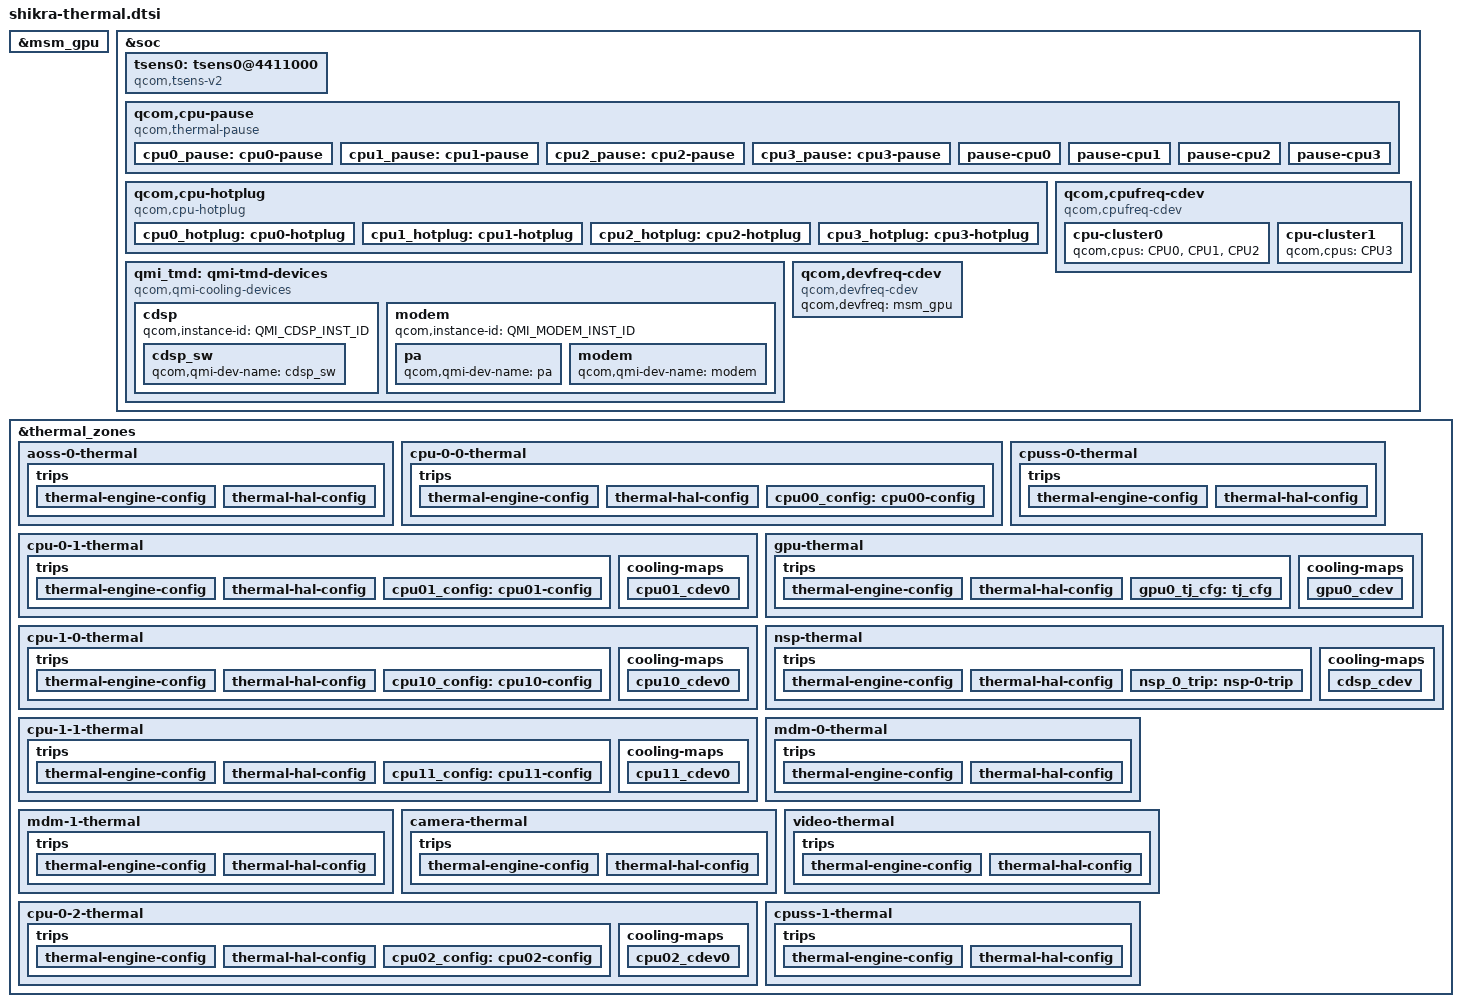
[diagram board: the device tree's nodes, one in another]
// SPDX-License-Identifier: BSD-3-Clause
/*
 * Copyright (c) Qualcomm Technologies, Inc. and/or its subsidiaries.
 */

#include <dt-bindings/thermal/thermal_qti.h>

&msm_gpu {
	#cooling-cells = <2>;
};

&soc {
	tsens0: tsens0@4411000 {
		compatible = "qcom,tsens-v2";
		reg = <0x04411000 0x1ff>, /* TM */
				<0x04410000 0x1ff>; /* SROT */
		#qcom,sensors = <14>;
		interrupts = <GIC_SPI 275 IRQ_TYPE_LEVEL_HIGH>,
				<GIC_SPI 190 IRQ_TYPE_LEVEL_HIGH>;
		interrupt-names = "uplow","critical";
		#thermal-sensor-cells = <1>;
	};

	qcom,cpu-pause {
		compatible = "qcom,thermal-pause";
		cpu0_pause: cpu0-pause {
			qcom,cpus = <&CPU0>;
			qcom,cdev-alias = "thermal-pause-1";
			#cooling-cells = <2>;
		};

		cpu1_pause: cpu1-pause {
			qcom,cpus = <&CPU1>;
			qcom,cdev-alias = "thermal-pause-2";
			#cooling-cells = <2>;
		};

		cpu2_pause: cpu2-pause {
			qcom,cpus = <&CPU2>;
			qcom,cdev-alias = "thermal-pause-4";
			#cooling-cells = <2>;
		};

		cpu3_pause: cpu3-pause {
			qcom,cpus = <&CPU3>;
			qcom,cdev-alias = "thermal-pause-8";
			#cooling-cells = <2>;
		};

		/* Thermal-engine cooling devices */
		pause-cpu0 {
			qcom,cpus = <&CPU0>;
			qcom,cdev-alias = "pause-cpu0";
		};

		pause-cpu1 {
			qcom,cpus = <&CPU1>;
			qcom,cdev-alias = "pause-cpu1";
		};

		pause-cpu2 {
			qcom,cpus = <&CPU2>;
			qcom,cdev-alias = "pause-cpu2";
		};

		pause-cpu3 {
			qcom,cpus = <&CPU3>;
			qcom,cdev-alias = "pause-cpu3";
		};
	};

	qcom,cpu-hotplug {
		compatible = "qcom,cpu-hotplug";
		cpu0_hotplug: cpu0-hotplug {
			qcom,cpu = <&CPU0>;
			qcom,cdev-alias = "cpu-hotplug0";
			#cooling-cells = <2>;
		};

		cpu1_hotplug: cpu1-hotplug {
			qcom,cpu = <&CPU1>;
			qcom,cdev-alias = "cpu-hotplug1";
			#cooling-cells = <2>;
		};

		cpu2_hotplug: cpu2-hotplug {
			qcom,cpu = <&CPU2>;
			qcom,cdev-alias = "cpu-hotplug2";
			#cooling-cells = <2>;
		};

		cpu3_hotplug: cpu3-hotplug {
			qcom,cpu = <&CPU3>;
			qcom,cdev-alias = "cpu-hotplug3";
			#cooling-cells = <2>;
		};
	};

	qcom,cpufreq-cdev {
		compatible = "qcom,cpufreq-cdev";
		cpu-cluster0 {
			qcom,cpus = <&CPU0 &CPU1 &CPU2>;
		};

		cpu-cluster1 {
			qcom,cpus = <&CPU3>;
		};
	};

	qmi_tmd: qmi-tmd-devices {
		compatible = "qcom,qmi-cooling-devices";
		cdsp {
			qcom,instance-id = <QMI_CDSP_INST_ID>;

			cdsp_sw: cdsp_sw {
				qcom,qmi-dev-name = "cdsp_sw";
				#cooling-cells = <2>;
			};
		};

		modem {
			qcom,instance-id = <QMI_MODEM_INST_ID>;

			pa: pa {
				qcom,qmi-dev-name = "pa";
				#cooling-cells = <2>;
			};

			modem: modem {
				qcom,qmi-dev-name = "modem";
				#cooling-cells = <2>;
			};
		};
	};

	qcom,devfreq-cdev {
		compatible = "qcom,devfreq-cdev";
		qcom,devfreq = <&msm_gpu>;
	};
};

&thermal_zones {
	aoss-0-thermal {
		polling-delay-passive = <0>;
		polling-delay = <0>;
		thermal-sensors = <&tsens0 0>;
		trips {
			thermal-engine-config {
				temperature = <125000>;
				hysteresis = <5000>;
				type = "passive";
			};

			thermal-hal-config {
				temperature = <115000>;
				hysteresis = <5000>;
				type = "passive";
			};
		};
	};

	cpu-0-0-thermal {
		polling-delay-passive = <0>;
		polling-delay = <0>;
		thermal-sensors = <&tsens0 1>;
		trips {
			thermal-engine-config {
				temperature = <125000>;
				hysteresis = <5000>;
				type = "passive";
			};

			thermal-hal-config {
				temperature = <115000>;
				hysteresis = <5000>;
				type = "passive";
			};

			cpu00_config: cpu00-config {
				temperature = <118000>;
				hysteresis = <10000>;
				type = "passive";
			};
		};
	};

	cpu-0-1-thermal {
		polling-delay-passive = <0>;
		polling-delay = <0>;
		thermal-sensors = <&tsens0 2>;
		trips {
			thermal-engine-config {
				temperature = <125000>;
				hysteresis = <5000>;
				type = "passive";
			};

			thermal-hal-config {
				temperature = <115000>;
				hysteresis = <5000>;
				type = "passive";
			};

			cpu01_config: cpu01-config {
				temperature = <118000>;
				hysteresis = <10000>;
				type = "passive";
			};
		};

		cooling-maps {
			cpu01_cdev0 {
				trip = <&cpu01_config>;
				cooling-device = <&cpu1_pause 0 1>;
			};
		};
	};

	cpu-1-0-thermal {
		polling-delay-passive = <0>;
		polling-delay = <0>;
		thermal-sensors = <&tsens0 3>;
		trips {
			thermal-engine-config {
				temperature = <125000>;
				hysteresis = <5000>;
				type = "passive";
			};

			thermal-hal-config {
				temperature = <115000>;
				hysteresis = <5000>;
				type = "passive";
			};

			cpu10_config: cpu10-config {
				temperature = <118000>;
				hysteresis = <10000>;
				type = "passive";
			};
		};

		cooling-maps {
			cpu10_cdev0 {
				trip = <&cpu10_config>;
				cooling-device = <&cpu3_pause 0 1>;
			};
		};
	};

	cpu-1-1-thermal {
		polling-delay-passive = <0>;
		polling-delay = <0>;
		thermal-sensors = <&tsens0 4>;
		trips {
			thermal-engine-config {
				temperature = <125000>;
				hysteresis = <5000>;
				type = "passive";
			};

			thermal-hal-config {
				temperature = <115000>;
				hysteresis = <5000>;
				type = "passive";
			};

			cpu11_config: cpu11-config {
				temperature = <118000>;
				hysteresis = <10000>;
				type = "passive";
			};
		};

		cooling-maps {
			cpu11_cdev0 {
				trip = <&cpu11_config>;
				cooling-device = <&cpu3_pause 0 1>;
			};
		};
	};

	cpuss-0-thermal {
		polling-delay-passive = <0>;
		polling-delay = <0>;
		thermal-sensors = <&tsens0 5>;
		trips {
			thermal-engine-config {
				temperature = <125000>;
				hysteresis = <5000>;
				type = "passive";
			};

			thermal-hal-config {
				temperature = <115000>;
				hysteresis = <5000>;
				type = "passive";
			};
		};
	};

	gpu-thermal {
		polling-delay-passive = <12>;
		polling-delay = <0>;
		thermal-sensors = <&tsens0 6>;
		trips {
			thermal-engine-config {
				temperature = <125000>;
				hysteresis = <5000>;
				type = "passive";
			};

			thermal-hal-config {
				temperature = <115000>;
				hysteresis = <5000>;
				type = "passive";
			};

			gpu0_tj_cfg: tj_cfg {
				temperature = <115000>;
				hysteresis = <5000>;
				type = "passive";
			};
		};

		cooling-maps {
			gpu0_cdev {
				trip = <&gpu0_tj_cfg>;
				cooling-device = <&msm_gpu 0 THERMAL_NO_LIMIT>;
			};
		};
	};

	nsp-thermal {
		polling-delay-passive = <12>;
		polling-delay = <0>;
		thermal-sensors = <&tsens0 7>;
		trips {
			thermal-engine-config {
				temperature = <125000>;
				hysteresis = <5000>;
				type = "passive";
			};

			thermal-hal-config {
				temperature = <115000>;
				hysteresis = <5000>;
				type = "passive";
			};

			nsp_0_trip: nsp-0-trip {
				temperature = <115000>;
				hysteresis = <5000>;
				type = "passive";
			};
		};

		cooling-maps {
			cdsp_cdev {
				trip = <&nsp_0_trip>;
				cooling-device = <&cdsp_sw 0 THERMAL_NO_LIMIT>;
			};
		};
	};

	mdm-0-thermal {
		polling-delay-passive = <0>;
		polling-delay = <0>;
		thermal-sensors = <&tsens0 8>;
		trips {
			thermal-engine-config {
				temperature = <125000>;
				hysteresis = <5000>;
				type = "passive";
			};

			thermal-hal-config {
				temperature = <115000>;
				hysteresis = <5000>;
				type = "passive";
			};
		};
	};

	mdm-1-thermal {
		polling-delay-passive = <0>;
		polling-delay = <0>;
		thermal-sensors = <&tsens0 9>;
		trips {
			thermal-engine-config {
				temperature = <125000>;
				hysteresis = <5000>;
				type = "passive";
			};

			thermal-hal-config {
				temperature = <115000>;
				hysteresis = <5000>;
				type = "passive";
			};
		};
	};

	camera-thermal {
		polling-delay-passive = <0>;
		polling-delay = <0>;
		thermal-sensors = <&tsens0 10>;
		trips {
			thermal-engine-config {
				temperature = <125000>;
				hysteresis = <5000>;
				type = "passive";
			};

			thermal-hal-config {
				temperature = <115000>;
				hysteresis = <5000>;
				type = "passive";
			};
		};
	};

	video-thermal {
		polling-delay-passive = <0>;
		polling-delay = <0>;
		thermal-sensors = <&tsens0 11>;
		trips {
			thermal-engine-config {
				temperature = <125000>;
				hysteresis = <5000>;
				type = "passive";
			};

			thermal-hal-config {
				temperature = <115000>;
				hysteresis = <5000>;
				type = "passive";
			};
		};
	};

	cpu-0-2-thermal {
		polling-delay-passive = <0>;
		polling-delay = <0>;
		thermal-sensors = <&tsens0 12>;
		trips {
			thermal-engine-config {
				temperature = <125000>;
				hysteresis = <5000>;
				type = "passive";
			};

			thermal-hal-config {
				temperature = <115000>;
				hysteresis = <5000>;
				type = "passive";
			};

			cpu02_config: cpu02-config {
				temperature = <118000>;
				hysteresis = <10000>;
				type = "passive";
			};
		};

		cooling-maps {
			cpu02_cdev0 {
				trip = <&cpu02_config>;
				cooling-device = <&cpu2_pause 0 1>;
			};
		};
	};

	cpuss-1-thermal {
		polling-delay-passive = <0>;
		polling-delay = <0>;
		thermal-sensors = <&tsens0 13>;
		trips {
			thermal-engine-config {
				temperature = <125000>;
				hysteresis = <5000>;
				type = "passive";
			};

			thermal-hal-config {
				temperature = <115000>;
				hysteresis = <5000>;
				type = "passive";
			};
		};
	};
};
